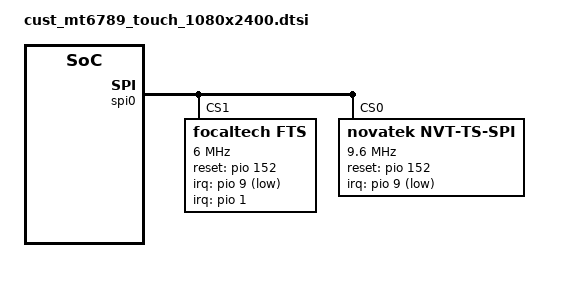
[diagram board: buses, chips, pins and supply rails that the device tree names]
/*
 * Copyright (c) 2019 MediaTek Inc.
 *
 * This program is free software; you can redistribute it and/or modify
 * it under the terms of the GNU General Public License version 2 as
 * published by the Free Software Foundation.
 *
 * This program is distributed in the hope that it will be useful,
 * but WITHOUT ANY WARRANTY; without even the implied warranty of
 * MERCHANTABILITY or FITNESS FOR A PARTICULAR PURPOSE.  See the
 * GNU General Public License for more details.
 */
/* TOUCH start */
&spi0 {
	focaltech@0 {
			compatible = "focaltech,fts";
			reg = <1>;
			status = "ok";
			spi-max-frequency = <6000000>;
			interrupt-parent = <&pio>;
			interrupts = <1 0x2>;
			focaltech,reset-gpio =  <&pio 152 0x00>;
			focaltech,irq-gpio = <&pio 9 0x2001>;
			focaltech,max-touch-number = <10>;
			focaltech,display-coords =  <0 0 1080 2408>;
		};
	novatek@0 {
		compatible = "novatek,NVT-ts-spi";
		reg = <0>; //Same as CS ID
		status = "ok";
		spi-max-frequency = <9600000>;	//4800000,9600000,15000000,19200000
		novatek,reset-gpio = <&pio 152 0x00>;
		novatek,irq-gpio = <&pio 9 0x2001>;
		/* 525 */
		//novatek,swrst-n8-addr = <0x01F01A>;
		/* 672A, 525B, 675, 526, 672C */
		novatek,swrst-n8-addr = <0x03F0FE>;
		novatek,spi-rd-fast-addr = <0x03F310>;
		/* MP */
		novatek,mp-support-dt;

		/* for L19A TM 6.58" panel module */
		novatek-mp-criteria-596E@0 {
			#address-cells = <1>;
			#size-cells = <0>;
			compatible = "novatek-mp-criteria-596E";

			/* MP Config */
			IC_X_CFG_SIZE = <16>;
			IC_Y_CFG_SIZE = <36>;
			IC_KEY_CFG_SIZE = <4>;
			X_Channel = <16>;
			Y_Channel = <36>;
			AIN_X = <0 1 2 3 4 5 6 7 8 9 10 11 12 13 14 15>;
			AIN_Y = <0 1 2 3 4 5 6 7 8 9 10 11 12 13 14 15 16 17 18 19 20 21 22 23 24 25 26 27 28 29 30 31 32 33 34 35>;
			AIN_KEY = <0 1 2 0xFF>;

			/*L19A code for HQ-192504  by gaoxue at 2022/4/25 start*/
			/* MP Criteria */
			PS_Config_Lmt_Short_Rawdata_P = <
				14008	14008	14008	14008	14008	14008	14008	14008	14008	14008	14008	14008	14008	14008	14008	14008
				14008	14008	14008	14008	14008	14008	14008	14008	14008	14008	14008	14008	14008	14008	14008	14008
				14008	14008	14008	14008	14008	14008	14008	14008	14008	14008	14008	14008	14008	14008	14008	14008
				14008	14008	14008	14008	14008	14008	14008	14008	14008	14008	14008	14008	14008	14008	14008	14008
				14008	14008	14008	14008	14008	14008	14008	14008	14008	14008	14008	14008	14008	14008	14008	14008
				14008	14008	14008	14008	14008	14008	14008	14008	14008	14008	14008	14008	14008	14008	14008	14008
				14008	14008	14008	14008	14008	14008	14008	14008	14008	14008	14008	14008	14008	14008	14008	14008
				14008	14008	14008	14008	14008	14008	14008	14008	14008	14008	14008	14008	14008	14008	14008	14008
				14008	14008	14008	14008	14008	14008	14008	14008	14008	14008	14008	14008	14008	14008	14008	14008
				14008	14008	14008	14008	14008	14008	14008	14008	14008	14008	14008	14008	14008	14008	14008	14008
				14008	14008	14008	14008	14008	14008	14008	14008	14008	14008	14008	14008	14008	14008	14008	14008
				14008	14008	14008	14008	14008	14008	14008	14008	14008	14008	14008	14008	14008	14008	14008	14008
				14008	14008	14008	14008	14008	14008	14008	14008	14008	14008	14008	14008	14008	14008	14008	14008
				14008	14008	14008	14008	14008	14008	14008	14008	14008	14008	14008	14008	14008	14008	14008	14008
				14008	14008	14008	14008	14008	14008	14008	14008	14008	14008	14008	14008	14008	14008	14008	14008
				14008	14008	14008	14008	14008	14008	14008	14008	14008	14008	14008	14008	14008	14008	14008	14008
				14008	14008	14008	14008	14008	14008	14008	14008	14008	14008	14008	14008	14008	14008	14008	14008
				14008	14008	14008	14008	14008	14008	14008	14008	14008	14008	14008	14008	14008	14008	14008	14008
				14008	14008	14008	14008	14008	14008	14008	14008	14008	14008	14008	14008	14008	14008	14008	14008
				14008	14008	14008	14008	14008	14008	14008	14008	14008	14008	14008	14008	14008	14008	14008	14008
				14008	14008	14008	14008	14008	14008	14008	14008	14008	14008	14008	14008	14008	14008	14008	14008
				14008	14008	14008	14008	14008	14008	14008	14008	14008	14008	14008	14008	14008	14008	14008	14008
				14008	14008	14008	14008	14008	14008	14008	14008	14008	14008	14008	14008	14008	14008	14008	14008
				14008	14008	14008	14008	14008	14008	14008	14008	14008	14008	14008	14008	14008	14008	14008	14008
				14008	14008	14008	14008	14008	14008	14008	14008	14008	14008	14008	14008	14008	14008	14008	14008
				14008	14008	14008	14008	14008	14008	14008	14008	14008	14008	14008	14008	14008	14008	14008	14008
				14008	14008	14008	14008	14008	14008	14008	14008	14008	14008	14008	14008	14008	14008	14008	14008
				14008	14008	14008	14008	14008	14008	14008	14008	14008	14008	14008	14008	14008	14008	14008	14008
				14008	14008	14008	14008	14008	14008	14008	14008	14008	14008	14008	14008	14008	14008	14008	14008
				14008	14008	14008	14008	14008	14008	14008	14008	14008	14008	14008	14008	14008	14008	14008	14008
				14008	14008	14008	14008	14008	14008	14008	14008	14008	14008	14008	14008	14008	14008	14008	14008
				14008	14008	14008	14008	14008	14008	14008	14008	14008	14008	14008	14008	14008	14008	14008	14008
				14008	14008	14008	14008	14008	14008	14008	14008	14008	14008	14008	14008	14008	14008	14008	14008
				14008	14008	14008	14008	14008	14008	14008	14008	14008	14008	14008	14008	14008	14008	14008	14008
				14008	14008	14008	14008	14008	14008	14008	14008	14008	14008	14008	14008	14008	14008	14008	14008
				14008	14008	14008	14008	14008	14008	14008	14008	14008	14008	14008	14008	14008	14008	14008	14008
				14008 14008 14008>;

			PS_Config_Lmt_Short_Rawdata_N = <
				10100	10100	10100	10100	10100	10100	10100	10100	10100	10100	10100	10100	10100	10100	10100	10100
				10100	10100	10100	10100	10100	10100	10100	10100	10100	10100	10100	10100	10100	10100	10100	10100
				10100	10100	10100	10100	10100	10100	10100	10100	10100	10100	10100	10100	10100	10100	10100	10100
				10100	10100	10100	10100	10100	10100	10100	10100	10100	10100	10100	10100	10100	10100	10100	10100
				10100	10100	10100	10100	10100	10100	10100	10100	10100	10100	10100	10100	10100	10100	10100	10100
				10100	10100	10100	10100	10100	10100	10100	10100	10100	10100	10100	10100	10100	10100	10100	10100
				10100	10100	10100	10100	10100	10100	10100	10100	10100	10100	10100	10100	10100	10100	10100	10100
				10100	10100	10100	10100	10100	10100	10100	10100	10100	10100	10100	10100	10100	10100	10100	10100
				10100	10100	10100	10100	10100	10100	10100	10100	10100	10100	10100	10100	10100	10100	10100	10100
				10100	10100	10100	10100	10100	10100	10100	10100	10100	10100	10100	10100	10100	10100	10100	10100
				10100	10100	10100	10100	10100	10100	10100	10100	10100	10100	10100	10100	10100	10100	10100	10100
				10100	10100	10100	10100	10100	10100	10100	10100	10100	10100	10100	10100	10100	10100	10100	10100
				10100	10100	10100	10100	10100	10100	10100	10100	10100	10100	10100	10100	10100	10100	10100	10100
				10100	10100	10100	10100	10100	10100	10100	10100	10100	10100	10100	10100	10100	10100	10100	10100
				10100	10100	10100	10100	10100	10100	10100	10100	10100	10100	10100	10100	10100	10100	10100	10100
				10100	10100	10100	10100	10100	10100	10100	10100	10100	10100	10100	10100	10100	10100	10100	10100
				10100	10100	10100	10100	10100	10100	10100	10100	10100	10100	10100	10100	10100	10100	10100	10100
				10100	10100	10100	10100	10100	10100	10100	10100	10100	10100	10100	10100	10100	10100	10100	10100
				10100	10100	10100	10100	10100	10100	10100	10100	10100	10100	10100	10100	10100	10100	10100	10100
				10100	10100	10100	10100	10100	10100	10100	10100	10100	10100	10100	10100	10100	10100	10100	10100
				10100	10100	10100	10100	10100	10100	10100	10100	10100	10100	10100	10100	10100	10100	10100	10100
				10100	10100	10100	10100	10100	10100	10100	10100	10100	10100	10100	10100	10100	10100	10100	10100
				10100	10100	10100	10100	10100	10100	10100	10100	10100	10100	10100	10100	10100	10100	10100	10100
				10100	10100	10100	10100	10100	10100	10100	10100	10100	10100	10100	10100	10100	10100	10100	10100
				10100	10100	10100	10100	10100	10100	10100	10100	10100	10100	10100	10100	10100	10100	10100	10100
				10100	10100	10100	10100	10100	10100	10100	10100	10100	10100	10100	10100	10100	10100	10100	10100
				10100	10100	10100	10100	10100	10100	10100	10100	10100	10100	10100	10100	10100	10100	10100	10100
				10100	10100	10100	10100	10100	10100	10100	10100	10100	10100	10100	10100	10100	10100	10100	10100
				10100	10100	10100	10100	10100	10100	10100	10100	10100	10100	10100	10100	10100	10100	10100	10100
				10100	10100	10100	10100	10100	10100	10100	10100	10100	10100	10100	10100	10100	10100	10100	10100
				10100	10100	10100	10100	10100	10100	10100	10100	10100	10100	10100	10100	10100	10100	10100	10100
				10100	10100	10100	10100	10100	10100	10100	10100	10100	10100	10100	10100	10100	10100	10100	10100
				10100	10100	10100	10100	10100	10100	10100	10100	10100	10100	10100	10100	10100	10100	10100	10100
				10100	10100	10100	10100	10100	10100	10100	10100	10100	10100	10100	10100	10100	10100	10100	10100
				10100	10100	10100	10100	10100	10100	10100	10100	10100	10100	10100	10100	10100	10100	10100	10100
				10100	10100	10100	10100	10100	10100	10100	10100	10100	10100	10100	10100	10100	10100	10100	10100
				10000 10000 10000>;

			PS_Config_Lmt_Open_Rawdata_P = <
				1664	1681	1698	1712	1706	1703	1688	65535	65535	1677	1692	1705	1720	1722	1701	1703
				1694	1703	1729	1750	1745	1744	1744	1716	1660	1703	1703	1717	1731	1724	1706	1716
				1640	1666	1688	1713	1709	1706	1706	1695	1674	1709	1710	1726	1740	1729	1710	1716
				1717	1717	1744	1775	1769	1765	1768	1754	1709	1727	1729	1747	1758	1741	1722	1729
				1716	1722	1744	1775	1772	1766	1765	1752	1757	1772	1769	1792	1797	1783	1764	1771
				1743	1734	1766	1800	1794	1794	1789	1778	1738	1740	1747	1766	1771	1752	1736	1745
				1762	1773	1787	1817	1818	1818	1811	1800	1797	1815	1806	1824	1827	1815	1793	1808
				1761	1773	1773	1815	1818	1820	1815	1801	1811	1825	1801	1831	1829	1815	1796	1807
				1797	1810	1825	1849	1853	1857	1850	1836	1813	1825	1818	1831	1825	1813	1790	1808
				1793	1803	1820	1841	1849	1849	1845	1825	1836	1850	1841	1850	1841	1827	1801	1827
				1793	1813	1824	1834	1852	1855	1848	1835	1845	1863	1852	1849	1848	1838	1811	1832
				1828	1848	1856	1885	1884	1891	1880	1864	1864	1885	1870	1885	1862	1855	1828	1848
				1853	1876	1885	1909	1899	1920	1909	1890	1864	1880	1870	1878	1838	1845	1820	1841
				1878	1902	1918	1940	1951	1951	1943	1916	1919	1937	1925	1939	1906	1895	1866	1892
				1859	1883	1892	1918	1926	1923	1913	1891	1895	1911	1897	1912	1881	1860	1841	1864
				1898	1925	1937	1961	1975	1955	1962	1943	1937	1950	1939	1955	1919	1884	1871	1898
				1888	1919	1919	1946	1957	1957	1941	1920	1954	1971	1955	1974	1934	1918	1881	1912
				1906	1937	1940	1968	1982	1983	1964	1948	1983	2000	1988	2002	1964	1947	1902	1939
				1932	1901	1891	1899	1874	1877	1859	1869	1824	1874	1862	1873	1871	1887	1874	1899
				1937	1908	1899	1905	1885	1887	1871	1874	1842	1892	1878	1891	1890	1906	1898	1916
				1948	1930	1918	1925	1902	1905	1888	1876	1899	1941	1932	1944	1943	1958	1948	1946
				1975	1951	1944	1953	1929	1930	1918	1919	1905	1950	1944	1955	1955	1968	1954	1965
				1979	1968	1955	1965	1944	1939	1925	1922	1899	1946	1936	1955	1951	1962	1950	1964
				1990	1976	1964	1979	1953	1948	1936	1936	1930	1974	1967	1985	1978	1985	1971	1983
				1981	1972	1962	1971	1948	1946	1930	1930	1899	1941	1933	1954	1947	1961	1947	1958
				1976	1974	1961	1972	1947	1950	1933	1934	1923	1964	1954	1972	1965	1976	1961	1969
				1990	1990	1983	1992	1967	1964	1950	1950	1913	1951	1944	1965	1960	1974	1964	1969
				1981	1983	1978	1986	1961	1961	1950	1946	1922	1961	1953	1972	1964	1978	1965	1971
				1985	1995	1983	1993	1965	1968	1954	1951	1911	1953	1940	1964	1954	1969	1957	1961
				2020	2028	2018	2031	2003	2002	1990	1985	1944	1985	1972	1995	1988	2003	1988	1993
				1964	1983	1974	1982	1954	1957	1943	1934	1932	1971	1965	1986	1978	1999	1978	1988
				2014	2031	2027	2035	2009	2011	1996	1988	1958	1996	1986	2006	2002	2017	1996	2003
				1992	2011	2007	2016	1990	1990	1976	1965	1958	1993	1982	2002	1996	2010	1988	1995
				2016	2035	2034	2045	2017	2023	2006	1997	1982	2018	2004	2025	2017	2032	2003	2013
				1982	2021	2018	2028	2003	2006	1988	1979	1979	2018	2002	2027	2018	2037	2006	2003
				1814	1863	1958	2034	2004	2007	1985	1975	1964	2006	1988	2011	2006	1961	1842	1804
				5120 5120 5120>;

			PS_Config_Lmt_Open_Rawdata_N = <
				713	720	727	733	731	730	723	(-65535)	(-65535)	718	725	730	737	738	729	730
				726	730	741	750	748	747	747	735	711	730	730	736	742	739	731	735
				703	714	723	734	732	731	731	726	717	732	733	739	745	741	733	735
				736	736	747	760	758	756	757	751	732	740	741	748	753	746	738	741
				735	738	747	760	759	757	756	751	753	759	758	768	770	764	756	759
				747	743	757	771	769	769	766	762	745	745	748	757	759	751	744	748
				755	760	766	778	779	779	776	771	770	778	774	781	783	778	768	775
				754	760	760	778	779	780	778	772	776	782	772	784	784	778	769	774
				770	775	782	792	794	796	793	787	777	782	779	784	782	777	767	775
				768	772	780	789	792	792	790	782	787	793	789	793	789	783	772	783
				768	777	781	786	793	795	792	786	790	798	793	792	792	787	776	785
				783	792	795	808	807	810	805	799	799	808	801	808	798	795	783	792
				794	804	808	818	814	823	818	810	799	805	801	805	787	790	780	789
				805	815	822	831	836	836	832	821	822	830	825	831	817	812	799	811
				796	807	811	822	825	824	820	810	812	819	813	819	806	797	789	799
				813	825	830	840	846	838	841	832	830	835	831	838	822	807	802	813
				809	822	822	834	838	838	832	823	837	844	838	846	829	822	806	819
				817	830	831	843	849	850	841	835	850	857	852	858	841	834	815	831
				828	814	810	814	803	804	796	801	781	803	798	802	802	808	803	814
				830	817	814	816	808	808	802	803	789	811	805	810	810	817	813	821
				835	827	822	825	815	816	809	804	814	832	828	833	832	839	835	834
				846	836	833	837	826	827	822	822	816	835	833	838	838	843	837	842
				848	843	838	842	833	831	825	823	814	834	829	838	836	841	835	841
				853	847	841	848	837	835	829	829	827	846	843	850	847	850	844	850
				849	845	841	844	835	834	827	827	814	832	828	837	834	840	834	839
				847	846	840	845	834	835	828	829	824	841	837	845	842	847	840	844
				853	853	850	853	843	841	835	835	820	836	833	842	840	846	841	844
				849	850	847	851	840	840	835	834	823	840	837	845	841	847	842	844
				850	855	850	854	842	843	837	836	819	837	831	841	837	844	838	840
				865	869	865	870	858	858	853	850	833	850	845	855	852	858	852	854
				841	850	846	849	837	838	832	829	828	844	842	851	847	856	847	852
				863	870	868	872	861	862	855	852	839	855	851	859	858	864	855	858
				853	862	860	864	853	853	847	842	839	854	849	858	855	861	852	855
				864	872	871	876	864	867	859	856	849	865	859	868	864	871	858	862
				849	866	865	869	858	859	852	848	848	865	858	868	865	873	859	858
				777	798	839	871	859	860	850	846	841	859	852	862	859	840	789	773
				(-511) (-511) (-511)>;

			PS_Config_Lmt_FW_Rawdata_P = <
				1127	1104	1122	1124	1120	1125	1114	65535	65535	1114	1117	1114	1122	1120	1118	1111
				1124	1092	1089	1107	1100	1110	1107	1120	1120	1125	1114	1118	1117	1118	1113	1122
				1107	1124	1113	1086	1110	1093	1094	1100	1097	1093	1092	1107	1086	1096	1103	1113
				1117	1100	1111	1108	1103	1104	1106	1134	1117	1132	1129	1128	1125	1121	1125	1117
				1121	1107	1114	1128	1117	1122	1120	1111	1128	1122	1114	1132	1117	1121	1121	1131
				1121	1114	1120	1104	1117	1108	1114	1124	1093	1094	1089	1087	1089	1093	1131	1118
				1132	1099	1096	1111	1103	1128	1111	1131	1129	1125	1122	1122	1122	1122	1106	1129
				1114	1114	1129	1138	1125	1134	1141	1135	1121	1120	1106	1108	1111	1101	1093	1120
				1128	1113	1114	1118	1118	1125	1115	1120	1131	1128	1127	1115	1125	1121	1115	1121
				1129	1118	1125	1145	1129	1139	1149	1100	1117	1114	1108	1103	1110	1110	1113	1122
				1132	1124	1111	1129	1120	1136	1128	1127	1138	1138	1110	1110	1118	1106	1103	1150
				1129	1111	1117	1120	1117	1131	1118	1141	1101	1101	1124	1124	1117	1138	1136	1117
				1110	1127	1121	1129	1134	1108	1128	1110	1120	1120	1110	1115	1121	1104	1120	1131
				1124	1129	1122	1118	1124	1114	1110	1124	1122	1121	1129	1132	1129	1121	1103	1101
				1113	1086	1101	1111	1115	1120	1117	1128	1117	1117	1124	1121	1122	1114	1117	1111
				1101	1139	1121	1115	1125	1110	1103	1127	1120	1117	1118	1110	1106	1103	1117	1141
				1100	1113	1121	1118	1115	1121	1118	1138	1134	1120	1108	1121	1107	1129	1124	1122
				1141	1120	1104	1127	1115	1120	1122	1122	1118	1117	1124	1117	1111	1111	1099	1107
				1134	1117	1131	1121	1132	1110	1101	1100	1115	1117	1122	1115	1120	1111	1100	1127
				1127	1129	1132	1125	1142	1124	1113	1115	1118	1118	1120	1117	1121	1117	1120	1113
				1115	1118	1117	1120	1117	1117	1110	1108	1104	1125	1127	1125	1113	1114	1118	1135
				1104	1113	1117	1129	1115	1128	1135	1138	1146	1129	1118	1125	1121	1125	1120	1142
				1131	1120	1124	1106	1120	1118	1120	1125	1125	1122	1117	1108	1118	1120	1100	1120
				1129	1129	1129	1136	1129	1131	1121	1125	1132	1108	1108	1094	1100	1103	1100	1127
				1124	1114	1120	1110	1129	1128	1111	1113	1142	1138	1138	1135	1134	1129	1120	1128
				1106	1099	1101	1113	1107	1111	1131	1138	1141	1120	1121	1114	1113	1128	1120	1117
				1127	1118	1124	1122	1118	1124	1129	1143	1141	1145	1142	1136	1135	1138	1141	1096
				1134	1122	1122	1120	1118	1117	1114	1120	1117	1125	1117	1128	1124	1124	1125	1125
				1131	1094	1094	1096	1100	1096	1101	1100	1113	1122	1114	1118	1120	1128	1121	1101
				1118	1121	1129	1120	1121	1121	1138	1145	1125	1139	1136	1131	1135	1139	1128	1108
				1136	1103	1110	1097	1103	1104	1110	1110	1136	1117	1138	1138	1139	1129	1129	1115
				1099	1134	1129	1135	1118	1136	1134	1138	1118	1125	1122	1117	1120	1118	1136	1117
				1113	1141	1129	1143	1117	1141	1124	1129	1118	1129	1113	1115	1106	1114	1135	1152
				1089	1134	1145	1135	1131	1138	1141	1110	1120	1125	1115	1122	1111	1120	1122	1115
				1122	1125	1121	1117	1127	1117	1120	1117	1121	1107	1118	1129	1120	1111	1115	1113
				1110	1106	1124	1128	1134	1124	1127	1110	1104	1110	1149	1101	1128	1122	1100	1110
				3840 3840 3840>;

			PS_Config_Lmt_FW_Rawdata_N = <
				483	473	481	481	480	482	477	(-65535)	(-65535)	477	478	477	481	480	479	476
				481	468	466	474	471	475	474	480	480	482	477	479	478	479	477	481
				474	481	477	465	475	468	469	471	470	468	468	474	465	469	472	477
				478	471	476	475	472	473	474	486	478	485	484	483	482	480	482	478
				480	474	477	483	478	481	480	476	483	481	477	485	478	480	480	484
				480	477	480	473	478	475	477	481	468	469	466	466	466	468	484	479
				485	471	469	476	472	483	476	484	484	482	481	481	481	481	474	484
				477	477	484	487	482	486	489	486	480	480	474	475	476	472	468	480
				483	477	477	479	479	482	478	480	484	483	483	478	482	480	478	480
				484	479	482	490	484	488	492	471	478	477	475	472	475	475	477	481
				485	481	476	484	480	487	483	483	487	487	475	475	479	474	472	493
				484	476	478	480	478	484	479	489	472	472	481	481	478	487	487	478
				475	483	480	484	486	475	483	475	480	480	475	478	480	473	480	484
				481	484	481	479	481	477	475	481	481	480	484	485	484	480	472	472
				477	465	472	476	478	480	478	483	478	478	481	480	481	477	478	476
				472	488	480	478	482	475	472	483	480	478	479	475	474	472	478	489
				471	477	480	479	478	480	479	487	486	480	475	480	474	484	481	481
				489	480	473	483	478	480	481	481	479	478	481	478	476	476	471	474
				486	478	484	480	485	475	472	471	478	478	481	478	480	476	471	483
				483	484	485	482	489	481	477	478	479	479	480	478	480	478	480	477
				478	479	478	480	478	478	475	475	473	482	483	482	477	477	479	486
				473	477	478	484	478	483	486	487	491	484	479	482	480	482	480	489
				484	480	481	474	480	479	480	482	482	481	478	475	479	480	471	480
				484	484	484	487	484	484	480	482	485	475	475	469	471	472	471	483
				481	477	480	475	484	483	476	477	489	487	487	486	486	484	480	483
				474	471	472	477	474	476	484	487	489	480	480	477	477	483	480	478
				483	479	481	481	479	481	484	490	489	490	489	487	486	487	489	469
				486	481	481	480	479	478	477	480	478	482	478	483	481	481	482	482
				484	469	469	469	471	469	472	471	477	481	477	479	480	483	480	472
				479	480	484	480	480	480	487	490	482	488	487	484	486	488	483	475
				487	472	475	470	472	473	475	475	487	478	487	487	488	484	484	478
				471	486	484	486	479	487	486	487	479	482	481	478	480	479	487	478
				477	489	484	490	478	489	481	484	479	484	477	478	474	477	486	493
				466	486	490	486	484	487	489	475	480	482	478	481	476	480	481	478
				481	482	480	478	483	478	480	478	480	474	479	484	480	476	478	477
				475	474	481	483	486	481	483	475	473	475	492	472	483	481	471	475
				240 240 240>;

			PS_Config_Lmt_FW_CC_P = <
				41	42	42	42	42	42	42	65535	65535	42	44	42	42	42	42	42
				42	42	42	42	42	42	42	44	42	42	42	42	42	42	42	42
				42	41	41	42	41	42	42	42	42	42	42	42	42	42	42	42
				42	42	42	42	42	42	42	44	42	42	42	42	42	42	42	44
				42	42	42	42	42	42	42	42	42	42	42	42	42	42	42	42
				44	42	42	42	42	42	42	44	42	42	42	42	42	42	42	42
				42	42	42	42	42	42	42	42	42	42	42	42	42	42	42	42
				44	42	42	42	42	42	42	44	42	42	42	42	42	42	42	44
				42	42	42	42	42	42	42	42	44	42	42	42	42	42	42	44
				44	42	42	42	42	44	42	44	44	42	42	42	42	42	42	44
				44	42	42	42	42	44	42	44	44	44	44	44	44	42	42	44
				42	42	42	42	42	44	42	44	44	44	42	42	42	42	42	44
				42	42	42	42	42	42	42	42	44	44	42	42	42	42	42	44
				44	42	44	44	44	44	44	44	44	44	42	42	42	42	42	44
				42	42	42	42	42	42	42	42	42	44	42	42	42	42	42	44
				44	42	42	44	44	44	44	45	44	44	42	42	44	42	42	44
				44	42	42	42	42	44	44	44	42	44	44	42	42	42	42	44
				42	42	42	42	42	44	44	44	42	44	44	42	42	42	42	44
				44	42	42	42	42	42	42	42	44	42	42	42	42	42	42	44
				44	42	42	42	42	44	44	44	44	44	44	42	42	42	42	44
				44	42	42	42	42	42	42	42	44	44	44	42	44	42	42	44
				45	44	44	44	44	44	44	44	44	44	44	42	44	42	42	44
				44	42	42	42	42	42	42	42	44	42	42	42	42	42	42	44
				44	42	42	42	42	42	44	44	44	42	42	42	42	42	42	44
				44	42	42	42	42	42	42	42	44	44	44	44	44	44	44	44
				44	44	44	44	44	44	44	44	44	44	44	44	44	44	44	44
				44	42	42	42	42	42	44	44	44	44	44	44	44	44	44	44
				44	42	44	44	44	44	44	44	44	44	44	44	44	44	44	44
				44	42	42	42	42	42	42	42	44	44	44	44	44	44	42	44
				44	44	44	44	44	44	44	44	44	44	44	44	44	44	44	44
				42	42	42	42	42	42	42	42	44	44	44	44	44	44	44	45
				44	44	44	44	44	44	44	44	44	44	44	44	44	44	42	44
				44	42	42	42	44	42	42	42	44	44	44	44	44	44	42	44
				45	44	44	44	44	44	44	44	44	44	42	42	42	44	42	44
				44	42	42	42	42	42	42	42	44	44	42	42	42	44	42	44
				42	42	42	44	44	44	44	44	44	44	42	44	42	42	42	42
				314 314 314>;

			PS_Config_Lmt_FW_CC_N = <
				18	19	19	19	19	19	19	(-65535)	(-65535)	19	19	19	19	19	19	19
				19	19	19	19	19	19	19	19	19	19	19	19	19	19	19	19
				19	18	18	19	18	19	19	19	19	19	19	19	19	19	19	19
				19	19	19	19	19	19	19	19	19	19	19	19	19	19	19	19
				19	19	19	19	19	19	19	19	19	19	19	19	19	19	19	19
				19	19	19	19	19	19	19	19	19	19	19	19	19	19	19	19
				19	19	19	19	19	19	19	19	19	19	19	19	19	19	19	19
				19	19	19	19	19	19	19	19	19	19	19	19	19	19	19	19
				19	19	19	19	19	19	19	19	19	19	19	19	19	19	19	19
				19	19	19	19	19	19	19	19	19	19	19	19	19	19	19	19
				19	19	19	19	19	19	19	19	19	19	19	19	19	19	19	19
				19	19	19	19	19	19	19	19	19	19	19	19	19	19	19	19
				19	19	19	19	19	19	19	19	19	19	19	19	19	19	19	19
				19	19	19	19	19	19	19	19	19	19	19	19	19	19	19	19
				19	19	19	19	19	19	19	19	19	19	19	19	19	19	19	19
				19	19	19	19	19	19	19	20	19	19	19	19	19	19	19	19
				19	19	19	19	19	19	19	19	19	19	19	19	19	19	19	19
				19	19	19	19	19	19	19	19	19	19	19	19	19	19	19	19
				19	19	19	19	19	19	19	19	19	19	19	19	19	19	19	19
				19	19	19	19	19	19	19	19	19	19	19	19	19	19	19	19
				19	19	19	19	19	19	19	19	19	19	19	19	19	19	19	19
				20	19	19	19	19	19	19	19	19	19	19	19	19	19	19	19
				19	19	19	19	19	19	19	19	19	19	19	19	19	19	19	19
				19	19	19	19	19	19	19	19	19	19	19	19	19	19	19	19
				19	19	19	19	19	19	19	19	19	19	19	19	19	19	19	19
				19	19	19	19	19	19	19	19	19	19	19	19	19	19	19	19
				19	19	19	19	19	19	19	19	19	19	19	19	19	19	19	19
				19	19	19	19	19	19	19	19	19	19	19	19	19	19	19	19
				19	19	19	19	19	19	19	19	19	19	19	19	19	19	19	19
				19	19	19	19	19	19	19	19	19	19	19	19	19	19	19	19
				19	19	19	19	19	19	19	19	19	19	19	19	19	19	19	20
				19	19	19	19	19	19	19	19	19	19	19	19	19	19	19	19
				19	19	19	19	19	19	19	19	19	19	19	19	19	19	19	19
				20	19	19	19	19	19	19	19	19	19	19	19	19	19	19	19
				19	19	19	19	19	19	19	19	19	19	19	19	19	19	19	19
				19	19	19	19	19	19	19	19	19	19	19	19	19	19	19	19
				0 0 0>;

			PS_Config_Lmt_FW_Diff_P = <
				50	50	50	50	50	50	50	65535	65535	50	50	50	50	50	50	50
				50	50	50	50	50	50	50	50	50	50	50	50	50	50	50	50
				50	50	50	50	50	50	50	50	50	50	50	50	50	50	50	50
				50	50	50	50	50	50	50	50	50	50	50	50	50	50	50	50
				50	50	50	50	50	50	50	50	50	50	50	50	50	50	50	50
				50	50	50	50	50	50	50	50	50	50	50	50	50	50	50	50
				50	50	50	50	50	50	50	50	50	50	50	50	50	50	50	50
				50	50	50	50	50	50	50	50	50	50	50	50	50	50	50	50
				50	50	50	50	50	50	50	50	50	50	50	50	50	50	50	50
				50	50	50	50	50	50	50	50	50	50	50	50	50	50	50	50
				50	50	50	50	50	50	50	50	50	50	50	50	50	50	50	50
				50	50	50	50	50	50	50	50	50	50	50	50	50	50	50	50
				50	50	50	50	50	50	50	50	50	50	50	50	50	50	50	50
				50	50	50	50	50	50	50	50	50	50	50	50	50	50	50	50
				50	50	50	50	50	50	50	50	50	50	50	50	50	50	50	50
				50	50	50	50	50	50	50	50	50	50	50	50	50	50	50	50
				50	50	50	50	50	50	50	50	50	50	50	50	50	50	50	50
				50	50	50	50	50	50	50	50	50	50	50	50	50	50	50	50
				50	50	50	50	50	50	50	50	50	50	50	50	50	50	50	50
				50	50	50	50	50	50	50	50	50	50	50	50	50	50	50	50
				50	50	50	50	50	50	50	50	50	50	50	50	50	50	50	50
				50	50	50	50	50	50	50	50	50	50	50	50	50	50	50	50
				50	50	50	50	50	50	50	50	50	50	50	50	50	50	50	50
				50	50	50	50	50	50	50	50	50	50	50	50	50	50	50	50
				50	50	50	50	50	50	50	50	50	50	50	50	50	50	50	50
				50	50	50	50	50	50	50	50	50	50	50	50	50	50	50	50
				50	50	50	50	50	50	50	50	50	50	50	50	50	50	50	50
				50	50	50	50	50	50	50	50	50	50	50	50	50	50	50	50
				50	50	50	50	50	50	50	50	50	50	50	50	50	50	50	50
				50	50	50	50	50	50	50	50	50	50	50	50	50	50	50	50
				50	50	50	50	50	50	50	50	50	50	50	50	50	50	50	50
				50	50	50	50	50	50	50	50	50	50	50	50	50	50	50	50
				50	50	50	50	50	50	50	50	50	50	50	50	50	50	50	50
				50	50	50	50	50	50	50	50	50	50	50	50	50	50	50	50
				50	50	50	50	50	50	50	50	50	50	50	50	50	50	50	50
				50	50	50	50	50	50	50	50	50	50	50	50	50	50	50	50
				75 75 75>;

			PS_Config_Lmt_FW_Diff_N = <
				(-50)	(-50)	(-50)	(-50)	(-50)	(-50)	(-50)	(-65535)	(-65535)	(-50)	(-50)	(-50)	(-50)	(-50)	(-50)	(-50)
				(-50)	(-50)	(-50)	(-50)	(-50)	(-50)	(-50)	(-50)	(-50)	(-50)	(-50)	(-50)	(-50)	(-50)	(-50)	(-50)
				(-50)	(-50)	(-50)	(-50)	(-50)	(-50)	(-50)	(-50)	(-50)	(-50)	(-50)	(-50)	(-50)	(-50)	(-50)	(-50)
				(-50)	(-50)	(-50)	(-50)	(-50)	(-50)	(-50)	(-50)	(-50)	(-50)	(-50)	(-50)	(-50)	(-50)	(-50)	(-50)
				(-50)	(-50)	(-50)	(-50)	(-50)	(-50)	(-50)	(-50)	(-50)	(-50)	(-50)	(-50)	(-50)	(-50)	(-50)	(-50)
				(-50)	(-50)	(-50)	(-50)	(-50)	(-50)	(-50)	(-50)	(-50)	(-50)	(-50)	(-50)	(-50)	(-50)	(-50)	(-50)
				(-50)	(-50)	(-50)	(-50)	(-50)	(-50)	(-50)	(-50)	(-50)	(-50)	(-50)	(-50)	(-50)	(-50)	(-50)	(-50)
				(-50)	(-50)	(-50)	(-50)	(-50)	(-50)	(-50)	(-50)	(-50)	(-50)	(-50)	(-50)	(-50)	(-50)	(-50)	(-50)
				(-50)	(-50)	(-50)	(-50)	(-50)	(-50)	(-50)	(-50)	(-50)	(-50)	(-50)	(-50)	(-50)	(-50)	(-50)	(-50)
				(-50)	(-50)	(-50)	(-50)	(-50)	(-50)	(-50)	(-50)	(-50)	(-50)	(-50)	(-50)	(-50)	(-50)	(-50)	(-50)
				(-50)	(-50)	(-50)	(-50)	(-50)	(-50)	(-50)	(-50)	(-50)	(-50)	(-50)	(-50)	(-50)	(-50)	(-50)	(-50)
				(-50)	(-50)	(-50)	(-50)	(-50)	(-50)	(-50)	(-50)	(-50)	(-50)	(-50)	(-50)	(-50)	(-50)	(-50)	(-50)
				(-50)	(-50)	(-50)	(-50)	(-50)	(-50)	(-50)	(-50)	(-50)	(-50)	(-50)	(-50)	(-50)	(-50)	(-50)	(-50)
				(-50)	(-50)	(-50)	(-50)	(-50)	(-50)	(-50)	(-50)	(-50)	(-50)	(-50)	(-50)	(-50)	(-50)	(-50)	(-50)
				(-50)	(-50)	(-50)	(-50)	(-50)	(-50)	(-50)	(-50)	(-50)	(-50)	(-50)	(-50)	(-50)	(-50)	(-50)	(-50)
				(-50)	(-50)	(-50)	(-50)	(-50)	(-50)	(-50)	(-50)	(-50)	(-50)	(-50)	(-50)	(-50)	(-50)	(-50)	(-50)
				(-50)	(-50)	(-50)	(-50)	(-50)	(-50)	(-50)	(-50)	(-50)	(-50)	(-50)	(-50)	(-50)	(-50)	(-50)	(-50)
				(-50)	(-50)	(-50)	(-50)	(-50)	(-50)	(-50)	(-50)	(-50)	(-50)	(-50)	(-50)	(-50)	(-50)	(-50)	(-50)
				(-50)	(-50)	(-50)	(-50)	(-50)	(-50)	(-50)	(-50)	(-50)	(-50)	(-50)	(-50)	(-50)	(-50)	(-50)	(-50)
				(-50)	(-50)	(-50)	(-50)	(-50)	(-50)	(-50)	(-50)	(-50)	(-50)	(-50)	(-50)	(-50)	(-50)	(-50)	(-50)
				(-50)	(-50)	(-50)	(-50)	(-50)	(-50)	(-50)	(-50)	(-50)	(-50)	(-50)	(-50)	(-50)	(-50)	(-50)	(-50)
				(-50)	(-50)	(-50)	(-50)	(-50)	(-50)	(-50)	(-50)	(-50)	(-50)	(-50)	(-50)	(-50)	(-50)	(-50)	(-50)
				(-50)	(-50)	(-50)	(-50)	(-50)	(-50)	(-50)	(-50)	(-50)	(-50)	(-50)	(-50)	(-50)	(-50)	(-50)	(-50)
				(-50)	(-50)	(-50)	(-50)	(-50)	(-50)	(-50)	(-50)	(-50)	(-50)	(-50)	(-50)	(-50)	(-50)	(-50)	(-50)
				(-50)	(-50)	(-50)	(-50)	(-50)	(-50)	(-50)	(-50)	(-50)	(-50)	(-50)	(-50)	(-50)	(-50)	(-50)	(-50)
				(-50)	(-50)	(-50)	(-50)	(-50)	(-50)	(-50)	(-50)	(-50)	(-50)	(-50)	(-50)	(-50)	(-50)	(-50)	(-50)
				(-50)	(-50)	(-50)	(-50)	(-50)	(-50)	(-50)	(-50)	(-50)	(-50)	(-50)	(-50)	(-50)	(-50)	(-50)	(-50)
				(-50)	(-50)	(-50)	(-50)	(-50)	(-50)	(-50)	(-50)	(-50)	(-50)	(-50)	(-50)	(-50)	(-50)	(-50)	(-50)
				(-50)	(-50)	(-50)	(-50)	(-50)	(-50)	(-50)	(-50)	(-50)	(-50)	(-50)	(-50)	(-50)	(-50)	(-50)	(-50)
				(-50)	(-50)	(-50)	(-50)	(-50)	(-50)	(-50)	(-50)	(-50)	(-50)	(-50)	(-50)	(-50)	(-50)	(-50)	(-50)
				(-50)	(-50)	(-50)	(-50)	(-50)	(-50)	(-50)	(-50)	(-50)	(-50)	(-50)	(-50)	(-50)	(-50)	(-50)	(-50)
				(-50)	(-50)	(-50)	(-50)	(-50)	(-50)	(-50)	(-50)	(-50)	(-50)	(-50)	(-50)	(-50)	(-50)	(-50)	(-50)
				(-50)	(-50)	(-50)	(-50)	(-50)	(-50)	(-50)	(-50)	(-50)	(-50)	(-50)	(-50)	(-50)	(-50)	(-50)	(-50)
				(-50)	(-50)	(-50)	(-50)	(-50)	(-50)	(-50)	(-50)	(-50)	(-50)	(-50)	(-50)	(-50)	(-50)	(-50)	(-50)
				(-50)	(-50)	(-50)	(-50)	(-50)	(-50)	(-50)	(-50)	(-50)	(-50)	(-50)	(-50)	(-50)	(-50)	(-50)	(-50)
				(-50)	(-50)	(-50)	(-50)	(-50)	(-50)	(-50)	(-50)	(-50)	(-50)	(-50)	(-50)	(-50)	(-50)	(-50)	(-50)
				(-75) (-75) (-75)>;

			PS_Config_Diff_Test_Frame = <50>;
                        /*L19A code for HQ-192504  by gaoxue at 2022/4/25 end*/
		};
	};
};
/* TOUCH end */

